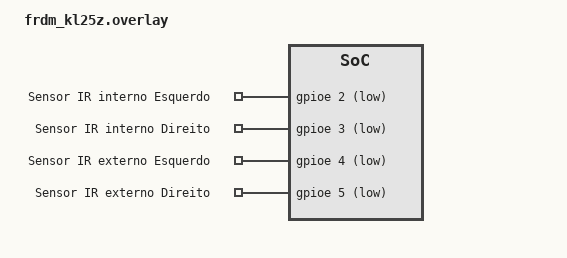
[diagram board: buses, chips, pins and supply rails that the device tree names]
&gpioe {
    status = "okay";
};
&gpioa {
    status = "okay";
};
&gpioc {
    status = "okay";
};
&gpiod {
    status = "okay";
};

/ {

    aliases {
        // Sensores IR
        sensor-int-esq = &sensor_int_esq_node;
        sensor-int-dir = &sensor_int_dir_node;
        sensor-ext-esq = &sensor_ext_esq_node;
        sensor-ext-dir = &sensor_ext_dir_node;

    };

    sensor_int_esq: sensor_int_esq {
        compatible = "gpio-keys";

        sensor_int_esq_node: sensor_int_esq_node {
            gpios = <&gpioe 2 GPIO_ACTIVE_LOW>;   // ajuste pino
            label = "Sensor IR interno Esquerdo";
        };
    };
    
    sensor_int_dir: sensor_int_dir{
        compatible = "gpio-keys";

        sensor_int_dir_node: sensor_int_dir_node {
            gpios = <&gpioe 3 GPIO_ACTIVE_LOW>;   // ajuste pino
            label = "Sensor IR interno Direito";
        };
    };

    sensor_ext_esq: sensor_ext_esq {
        compatible = "gpio-keys";

        sensor_ext_esq_node: sensor_ext_esq_node {
            gpios = <&gpioe 4 GPIO_ACTIVE_LOW>;   // ajuste pino
            label = "Sensor IR externo Esquerdo";
        };
    };
    
    sensor_ext_dir: sensor_ext_dir{
        compatible = "gpio-keys";

        sensor_ext_dir_node: sensor_ext_dir_node {
            gpios = <&gpioe 5 GPIO_ACTIVE_LOW>;   // ajuste pino
            label = "Sensor IR externo Direito";
        };
    };

};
